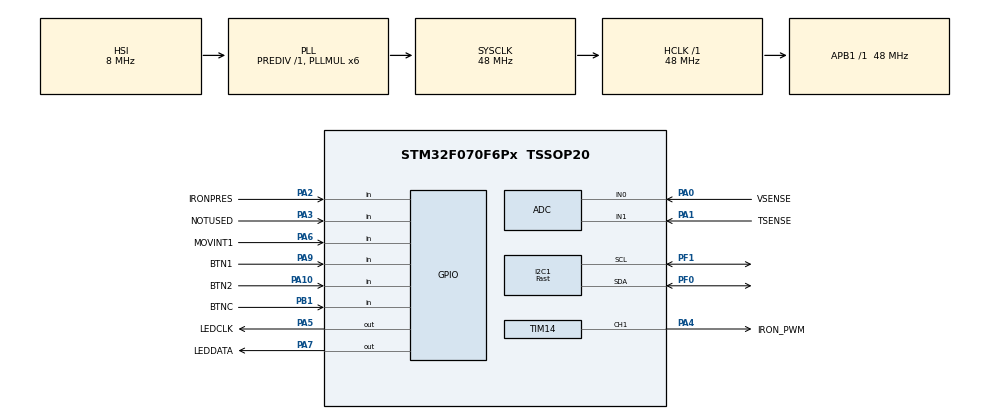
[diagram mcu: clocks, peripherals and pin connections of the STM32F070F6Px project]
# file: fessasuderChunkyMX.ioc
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ADC.ClockPrescaler=ADC_CLOCK_ASYNC_DIV1
ADC.ContinuousConvMode=ENABLE
ADC.ExternalTrigConv=ADC_SOFTWARE_START
ADC.SamplingTime=ADC_SAMPLETIME_239CYCLES_5
I2C1.I2C_Speed_Mode=I2C_Fast
I2C1.Speed=400
I2C1.Timing=0x2010091A
Mcu.Family=STM32F0
Mcu.Name=STM32F070F6Px
Mcu.Package=TSSOP20
NVIC.TIM14_IRQn=true\:0\:0\:false\:false\:true\:true\:true
PA0.GPIO_Label=VSENSE
PA0.Mode=IN0
PA0.Signal=ADC_IN0
PA1.GPIO_Label=TSENSE
PA1.Mode=IN1
PA1.Signal=ADC_IN1
PA10.GPIO_Label=BTN2
PA10.GPIO_PuPd=GPIO_PULLUP
PA10.Signal=GPIO_Input
PA13.Mode=Serial_Wire
PA13.Signal=SYS_SWDIO
PA14.Mode=Serial_Wire
PA14.Signal=SYS_SWCLK
PA2.GPIO_Label=IRONPRES
PA2.Signal=GPIO_Input
PA3.GPIO_Label=NOTUSED
PA3.Signal=GPIO_Input
PA4.GPIO_Label=IRON_PWM
PA4.GPIO_Speed=GPIO_SPEED_FREQ_MEDIUM
PA4.Signal=S_TIM14_CH1
PA5.GPIO_Label=LEDCLK
PA5.Signal=GPIO_Output
PA6.GPIO_Label=MOVINT1
PA6.GPIO_PuPd=GPIO_PULLDOWN
PA6.Signal=GPIO_Input
PA7.GPIO_Label=LEDDATA
PA7.Signal=GPIO_Output
PA9.GPIO_Label=BTN1
PA9.GPIO_PuPd=GPIO_PULLUP
PA9.Signal=GPIO_Input
PB1.GPIO_Label=BTNC
PB1.GPIO_PuPd=GPIO_PULLUP
PB1.Signal=GPIO_Input
PF0-OSC_IN.Mode=I2C
PF0-OSC_IN.Signal=I2C1_SDA
PF1-OSC_OUT.Mode=I2C
PF1-OSC_OUT.Signal=I2C1_SCL
ProjectManager.HeapSize=0x200
ProjectManager.StackSize=0x400
ProjectManager.TargetToolchain=SW4STM32
RCC.AHBFreq_Value=48000000
RCC.APB1Freq_Value=48000000
RCC.APB1TimFreq_Value=48000000
RCC.HCLKFreq_Value=48000000
RCC.I2c1ClockSelection=RCC_I2C1CLKSOURCE_SYSCLK
RCC.PLLMUL=RCC_PLL_MUL6
RCC.SYSCLKFreq_VALUE=48000000
RCC.SYSCLKSource=RCC_SYSCLKSOURCE_PLLCLK
SH.S_TIM14_CH1.0=TIM14_CH1,PWM Generation1 CH1
TIM14.AutoReloadPreload=TIM_AUTORELOAD_PRELOAD_ENABLE
TIM14.Channel=TIM_CHANNEL_1
TIM14.Period=999
TIM14.Prescaler=1
TIM17.Period=0xFFFF
TIM17.Prescaler=48000-1
VP_RTC_VS_RTC_Activate.Mode=RTC_Enabled
VP_TIM14_VS_ClockSourceINT.Mode=Enable_Timer
VP_TIM17_VS_ClockSourceINT.Mode=Enable_Timer
board=custom

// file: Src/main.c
/* USER CODE BEGIN Header */
/**
  ******************************************************************************
  * @file           : main.c
  * @brief          : Main program body
  ******************************************************************************
  * @attention
  *
  * <h2><center>&copy; Copyright (c) 2021 STMicroelectronics.
  * All rights reserved.</center></h2>
  *
  * This software component is licensed by ST under BSD 3-Clause license,
  * the "License"; You may not use this file except in compliance with the
  * License. You may obtain a copy of the License at:
  *                        opensource.org/licenses/BSD-3-Clause
  *
  ******************************************************************************
  */
/* USER CODE END Header */

#include "main.h"

/* USER CODE BEGIN Includes */

#include <stdint.h>
#include "application_oled.h"
#include "stm32_core.h"
#include "stm32_eeprom.h"
#include "stm32_iic.h"
#include "stm32_io.h"
#include "stm32_acc.h"
#include "stm32_neopixel.h"
/* USER CODE END Includes */

ADC_HandleTypeDef hadc;

I2C_HandleTypeDef hi2c1;

RTC_HandleTypeDef hrtc;

TIM_HandleTypeDef htim14;
TIM_HandleTypeDef htim17;

void SystemClock_Config(void);
static void MX_GPIO_Init(void);
static void MX_ADC_Init(void);
static void MX_I2C1_Init(void);
static void MX_TIM14_Init(void);
static void MX_TIM17_Init(void);
static void MX_RTC_Init(void);

int main(void)
{

  /* MCU Configuration--------------------------------------------------------*/

  /* Reset of all peripherals, Initializes the Flash interface and the Systick. */
  HAL_Init();

  /* Configure the system clock */
  SystemClock_Config();

  /* Initialize all configured peripherals */
  MX_GPIO_Init();
  MX_ADC_Init();
  MX_I2C1_Init();
  MX_TIM14_Init();
  MX_TIM17_Init();
  MX_RTC_Init();
  /* USER CODE BEGIN 2 */
  APP_startup();
  /* USER CODE END 2 */

  /* Infinite loop */
  /* USER CODE BEGIN WHILE */
  while (1)
  {
	APP_loop();
	//HAL_GPIO_WritePin(LEDDATA_GPIO_Port, LEDDATA_Pin, GPIO_PIN_RESET);

    /* USER CODE END WHILE */

  }
}

void SystemClock_Config(void)
{
  RCC_OscInitTypeDef RCC_OscInitStruct = {0};
  RCC_ClkInitTypeDef RCC_ClkInitStruct = {0};
  RCC_PeriphCLKInitTypeDef PeriphClkInit = {0};

  /** Initializes the CPU, AHB and APB busses clocks
  */
  RCC_OscInitStruct.OscillatorType = RCC_OSCILLATORTYPE_HSI|RCC_OSCILLATORTYPE_HSI14
                              |RCC_OSCILLATORTYPE_LSI;
  RCC_OscInitStruct.HSIState = RCC_HSI_ON;
  RCC_OscInitStruct.HSI14State = RCC_HSI14_ON;
  RCC_OscInitStruct.HSICalibrationValue = RCC_HSICALIBRATION_DEFAULT;
  RCC_OscInitStruct.HSI14CalibrationValue = 16;
  RCC_OscInitStruct.LSIState = RCC_LSI_ON;
  RCC_OscInitStruct.PLL.PLLState = RCC_PLL_ON;
  RCC_OscInitStruct.PLL.PLLSource = RCC_PLLSOURCE_HSI;
  RCC_OscInitStruct.PLL.PLLMUL = RCC_PLL_MUL6;
  RCC_OscInitStruct.PLL.PREDIV = RCC_PREDIV_DIV1;
  if (HAL_RCC_OscConfig(&RCC_OscInitStruct) != HAL_OK)
  {
    Error_Handler();
  }
  /** Initializes the CPU, AHB and APB busses clocks
  */
  RCC_ClkInitStruct.ClockType = RCC_CLOCKTYPE_HCLK|RCC_CLOCKTYPE_SYSCLK
                              |RCC_CLOCKTYPE_PCLK1;
  RCC_ClkInitStruct.SYSCLKSource = RCC_SYSCLKSOURCE_PLLCLK;
  RCC_ClkInitStruct.AHBCLKDivider = RCC_SYSCLK_DIV1;
  RCC_ClkInitStruct.APB1CLKDivider = RCC_HCLK_DIV1;

  if (HAL_RCC_ClockConfig(&RCC_ClkInitStruct, FLASH_LATENCY_1) != HAL_OK)
  {
    Error_Handler();
  }
  PeriphClkInit.PeriphClockSelection = RCC_PERIPHCLK_I2C1|RCC_PERIPHCLK_RTC;
  PeriphClkInit.I2c1ClockSelection = RCC_I2C1CLKSOURCE_SYSCLK;
  PeriphClkInit.RTCClockSelection = RCC_RTCCLKSOURCE_LSI;
  if (HAL_RCCEx_PeriphCLKConfig(&PeriphClkInit) != HAL_OK)
  {
    Error_Handler();
  }
}

static void MX_ADC_Init(void)
{

  ADC_ChannelConfTypeDef sConfig = {0};

  /** Configure the global features of the ADC (Clock, Resolution, Data Alignment and number of conversion)
  */
  hadc.Instance = ADC1;
  hadc.Init.ClockPrescaler = ADC_CLOCK_ASYNC_DIV1;
  hadc.Init.Resolution = ADC_RESOLUTION_12B;
  hadc.Init.DataAlign = ADC_DATAALIGN_RIGHT;
  hadc.Init.ScanConvMode = ADC_SCAN_DIRECTION_FORWARD;
  hadc.Init.EOCSelection = ADC_EOC_SINGLE_CONV;
  hadc.Init.LowPowerAutoWait = DISABLE;
  hadc.Init.LowPowerAutoPowerOff = DISABLE;
  hadc.Init.ContinuousConvMode = ENABLE;
  hadc.Init.DiscontinuousConvMode = DISABLE;
  hadc.Init.ExternalTrigConv = ADC_SOFTWARE_START;
  hadc.Init.ExternalTrigConvEdge = ADC_EXTERNALTRIGCONVEDGE_NONE;
  hadc.Init.DMAContinuousRequests = DISABLE;
  hadc.Init.Overrun = ADC_OVR_DATA_PRESERVED;
  if (HAL_ADC_Init(&hadc) != HAL_OK)
  {
    Error_Handler();
  }
  /** Configure for the selected ADC regular channel to be converted.
  */
  sConfig.Channel = ADC_CHANNEL_0;
  sConfig.Rank = ADC_RANK_CHANNEL_NUMBER;
  sConfig.SamplingTime = ADC_SAMPLETIME_239CYCLES_5;
  if (HAL_ADC_ConfigChannel(&hadc, &sConfig) != HAL_OK)
  {
    Error_Handler();
  }
  /** Configure for the selected ADC regular channel to be converted.
  */
  sConfig.Channel = ADC_CHANNEL_1;
  if (HAL_ADC_ConfigChannel(&hadc, &sConfig) != HAL_OK)
  {
    Error_Handler();
  }

}

static void MX_I2C1_Init(void)
{

  hi2c1.Instance = I2C1;
  hi2c1.Init.Timing = 0x2010091A;
  hi2c1.Init.OwnAddress1 = 0;
  hi2c1.Init.AddressingMode = I2C_ADDRESSINGMODE_7BIT;
  hi2c1.Init.DualAddressMode = I2C_DUALADDRESS_DISABLE;
  hi2c1.Init.OwnAddress2 = 0;
  hi2c1.Init.OwnAddress2Masks = I2C_OA2_NOMASK;
  hi2c1.Init.GeneralCallMode = I2C_GENERALCALL_DISABLE;
  hi2c1.Init.NoStretchMode = I2C_NOSTRETCH_DISABLE;
  if (HAL_I2C_Init(&hi2c1) != HAL_OK)
  {
    Error_Handler();
  }
  /** Configure Analogue filter
  */
  if (HAL_I2CEx_ConfigAnalogFilter(&hi2c1, I2C_ANALOGFILTER_ENABLE) != HAL_OK)
  {
    Error_Handler();
  }
  /** Configure Digital filter
  */
  if (HAL_I2CEx_ConfigDigitalFilter(&hi2c1, 0) != HAL_OK)
  {
    Error_Handler();
  }

}

static void MX_RTC_Init(void)
{

  /** Initialize RTC Only
  */
  hrtc.Instance = RTC;
  hrtc.Init.HourFormat = RTC_HOURFORMAT_24;
  hrtc.Init.AsynchPrediv = 127;
  hrtc.Init.SynchPrediv = 255;
  hrtc.Init.OutPut = RTC_OUTPUT_DISABLE;
  hrtc.Init.OutPutPolarity = RTC_OUTPUT_POLARITY_HIGH;
  hrtc.Init.OutPutType = RTC_OUTPUT_TYPE_OPENDRAIN;
  if (HAL_RTC_Init(&hrtc) != HAL_OK)
  {
    Error_Handler();
  }

}

static void MX_TIM14_Init(void)
{

  TIM_OC_InitTypeDef sConfigOC = {0};

  htim14.Instance = TIM14;
  htim14.Init.Prescaler = 1;
  htim14.Init.CounterMode = TIM_COUNTERMODE_UP;
  htim14.Init.Period = 999;
  htim14.Init.ClockDivision = TIM_CLOCKDIVISION_DIV1;
  htim14.Init.AutoReloadPreload = TIM_AUTORELOAD_PRELOAD_ENABLE;
  if (HAL_TIM_Base_Init(&htim14) != HAL_OK)
  {
    Error_Handler();
  }
  if (HAL_TIM_PWM_Init(&htim14) != HAL_OK)
  {
    Error_Handler();
  }
  sConfigOC.OCMode = TIM_OCMODE_PWM1;
  sConfigOC.Pulse = 0;
  sConfigOC.OCPolarity = TIM_OCPOLARITY_HIGH;
  sConfigOC.OCFastMode = TIM_OCFAST_DISABLE;
  if (HAL_TIM_PWM_ConfigChannel(&htim14, &sConfigOC, TIM_CHANNEL_1) != HAL_OK)
  {
    Error_Handler();
  }
  /* USER CODE BEGIN TIM14_Init 2 */
  HAL_TIM_PWM_Start(&htim14, TIM_CHANNEL_1);

  /* USER CODE END TIM14_Init 2 */
  HAL_TIM_MspPostInit(&htim14);

}

static void MX_TIM17_Init(void)
{

  htim17.Instance = TIM17;
  htim17.Init.Prescaler = 48000-1;
  htim17.Init.CounterMode = TIM_COUNTERMODE_UP;
  htim17.Init.Period = 0xFFFF;
  htim17.Init.ClockDivision = TIM_CLOCKDIVISION_DIV1;
  htim17.Init.RepetitionCounter = 0;
  htim17.Init.AutoReloadPreload = TIM_AUTORELOAD_PRELOAD_DISABLE;
  if (HAL_TIM_Base_Init(&htim17) != HAL_OK)
  {
    Error_Handler();
  }

}

static void MX_GPIO_Init(void)
{
  GPIO_InitTypeDef GPIO_InitStruct = {0};

  /* GPIO Ports Clock Enable */
  __HAL_RCC_GPIOF_CLK_ENABLE();
  __HAL_RCC_GPIOA_CLK_ENABLE();
  __HAL_RCC_GPIOB_CLK_ENABLE();

  /*Configure GPIO pin Output Level */
  HAL_GPIO_WritePin(GPIOA, LEDCLK_Pin|LEDDATA_Pin, GPIO_PIN_RESET);

  /*Configure GPIO pins : IRONPRES_Pin NOTUSED_Pin */
  GPIO_InitStruct.Pin = IRONPRES_Pin|NOTUSED_Pin;
  GPIO_InitStruct.Mode = GPIO_MODE_INPUT;
  GPIO_InitStruct.Pull = GPIO_NOPULL;
  HAL_GPIO_Init(GPIOA, &GPIO_InitStruct);

  /*Configure GPIO pins : LEDCLK_Pin LEDDATA_Pin */
  GPIO_InitStruct.Pin = LEDCLK_Pin|LEDDATA_Pin;
  GPIO_InitStruct.Mode = GPIO_MODE_OUTPUT_PP;
  GPIO_InitStruct.Pull = GPIO_NOPULL;
  GPIO_InitStruct.Speed = GPIO_SPEED_FREQ_LOW;
  HAL_GPIO_Init(GPIOA, &GPIO_InitStruct);

  /*Configure GPIO pin : MOVINT1_Pin */
  GPIO_InitStruct.Pin = MOVINT1_Pin;
  GPIO_InitStruct.Mode = GPIO_MODE_INPUT;
  GPIO_InitStruct.Pull = GPIO_PULLDOWN;
  HAL_GPIO_Init(MOVINT1_GPIO_Port, &GPIO_InitStruct);

  /*Configure GPIO pin : BTNC_Pin */
  GPIO_InitStruct.Pin = BTNC_Pin;
  GPIO_InitStruct.Mode = GPIO_MODE_INPUT;
  GPIO_InitStruct.Pull = GPIO_PULLUP;
  HAL_GPIO_Init(BTNC_GPIO_Port, &GPIO_InitStruct);

  /*Configure GPIO pins : BTN1_Pin BTN2_Pin */
  GPIO_InitStruct.Pin = BTN1_Pin|BTN2_Pin;
  GPIO_InitStruct.Mode = GPIO_MODE_INPUT;
  GPIO_InitStruct.Pull = GPIO_PULLUP;
  HAL_GPIO_Init(GPIOA, &GPIO_InitStruct);

}

void Error_Handler(void)
{
}

/************************ (C) COPYRIGHT STMicroelectronics *****END OF FILE****/
